# DCC1_SR2 register map
Vendor: Texas Instruments
Peripheral module from a debugger description file (folder DM50x).
Registers are 32-bit, access per field, reset 0x0 unless marked. A register's access mark holds for its fields unless they carry their own. Offsets are as the file gives them; lines under a group give offsets from that group; [hi:lo] are bit positions; {n}, {i} and the like mark numbered series; 'fields as' and 'values as' point back to an identical list; <NAME> marks a mode.

## DCC1_SR2
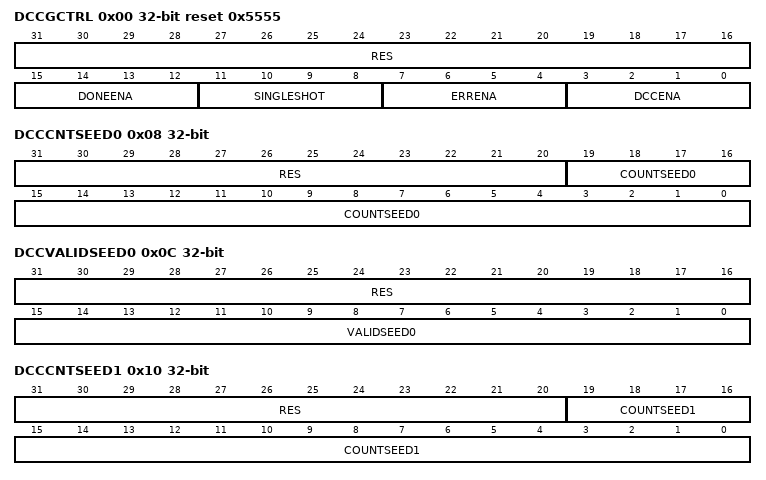
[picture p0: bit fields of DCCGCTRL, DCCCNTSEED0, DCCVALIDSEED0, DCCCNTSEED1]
0x00 DCCGCTRL reset 0x5555 — DCC Global Control RegisterNOTE: For SR1.0 physical addresses, see
  [31:16] RES ro — User, privilege, and debug mode reads return 0 and writes have no effect
  [15:12] DONEENA rw — The DONEENA bit enables/disables the done interrupt signal, but has no effect on the done status flag inDCCSTAT register. User, privilege, and debug mode (read): 0101 = the done signal is disabled others = the done signal is enabled Privilege and debug mode (write): 0101 = disable done signal generation others = enable done signal generation
  [11:8] SINGLESHOT rw — The SINGLESHOT bit enables/disables repetitive operation of the DCC. User, privilege, and debug mode (read): 1010 = stop counting when counter0 and valid0 both reach zero 1011 = stop counting when counter1 reaches zero others = continuously repeat (until error) Privilege and debug mode (write): 1010 = stop counting when counter0 and valid0 both reach zero 1011 = stop counting when counter1 reaches zero others = continuously repeat (until error)
  [7:4] ERRENA rw — The ERRENA bit enables/disables the error signal. User, privilege, and debug mode (read): 0101 = the error signal is disabled others = the error signal is enabled Privilege and debug mode (write): 0101 = disable error signal generation others = enable error signal generation
  [3:0] DCCENA rw — The DCCENA bit starts and stops the operation of the dcc. User, privilege, and debug mode (read): 0101 = counters are stopped others = counters are running Privilege and debug mode (write): 0101 = stop counters and error-checking others = load the counters with their seed values and begin counting
0x04 DCCREV ro reset not defined — DCC Revision IDNOTE: For SR1.0 physical addresses, see
  [31:0] REVISION — IP Revision
0x08 DCCCNTSEED0 — Count0 Seed Value RegisterNOTE: For SR1.0 physical addresses, see
  [31:20] RES ro — User, privilege, and debug mode reads return 0 and writes have no effect
  [19:0] COUNTSEED0 rw — This field contains the seed value that gets loaded into counter 0 (clock source 0). User, privilege, and debug mode (read): Returns the current seed value for COUNT0. Privilege and debug mode (write): Sets the current seed value for COUNT0.
0x0C DCCVALIDSEED0 — Valid0 Seed Value RegisterNOTE: For SR1.0 physical addresses, see
  [31:16] RES ro — User, privilege, and debug mode reads return 0 and writes have no effect
  [15:0] VALIDSEED0 rw — This field contains the seed value that gets loaded into the valid duration counter for clock source 0. User, privilege, and debug mode (read): Returns the current seed value for VALID0. Privilege and debug mode (write): Sets the current seed value for VALID0.
0x10 DCCCNTSEED1 — Count1 Seed Value RegisterNOTE: For SR1.0 physical addresses, see
  [31:20] RES ro — User, privilege, and debug mode reads return 0 and writes have no effect
  [19:0] COUNTSEED1 rw — This field contains the seed value that gets loaded into counter 1 (clock source 1). User, privilege, and debug mode (read): Returns the current seed value for COUNT1. Privilege and debug mode (write): Sets the current seed value for COUNT1.
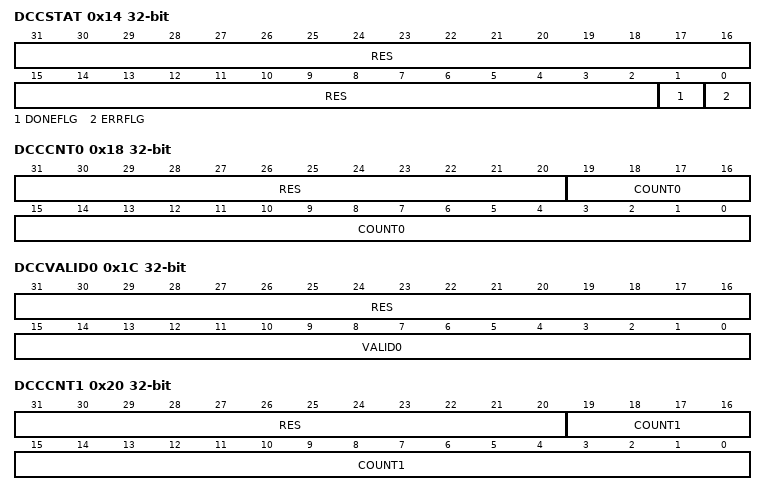
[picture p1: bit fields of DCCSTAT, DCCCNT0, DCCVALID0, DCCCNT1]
0x14 DCCSTAT — DCC Status RegisterNOTE: For SR1.0 physical addresses, see
  [31:2] RES ro
  [1] DONEFLG rw — Indicates when single-shot mode is complete without error. Writing a ?1? to this bit clears the flag. User, privilege, and debug mode (read): 0 = single-shot mode is not done 1 = single-shot mode is done Privilege and debug mode (write): 0 = no effect 1 = clear the done flag
  [0] ERRFLG rw — Indicates whether or not an error has occurred. Writing a ?1? to this bit clears the flag. User, privilege, and debug mode (read): 0 = an error has not occurred 1 = an error has occurred Privilege and debug mode (write): 0 = no effect 1 = clear the error flag
0x18 DCCCNT0 ro — Count0 Value RegisterNOTE: For SR1.0 physical addresses, see
  [31:20] RES — User, privilege, and debug mode reads return 0 and writes have no effect
  [19:0] COUNT0 — This field contains the current value of counter 0. User, privilege, and debug mode (read): Returns the current value for counter 0. Privilege and debug mode (write): Writes have no effect.
0x1C DCCVALID0 ro — Valid0 Value RegisterNOTE: For SR1.0 physical addresses, see
  [31:16] RES — User, privilege, and debug mode reads return 0 and writes have no effect
  [15:0] VALID0 — This field contains the current value of valid counter 0. User, privilege, and debug mode (read): Returns the current value for valid counter 0. Privilege and debug mode (write): writes have no effect.
0x20 DCCCNT1 ro — Count1 Value RegisterNOTE: For SR1.0 physical addresses, see
  [31:20] RES — User, privilege, and debug mode reads return 0 and writes have no effect
  [19:0] COUNT1 — This field contains the current value of counter 1. User, privilege, and debug mode (read): Returns the current value for counter 1. Privilege and debug mode (write): writes have no effect.
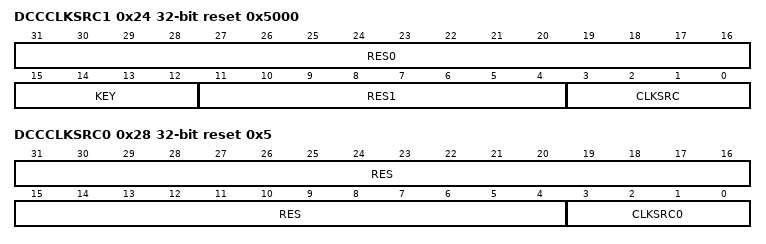
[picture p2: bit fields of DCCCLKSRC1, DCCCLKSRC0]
0x24 DCCCLKSRC1 reset 0x5000 — Clock Source Selection Register 1NOTE: For SR1.0 physical addresses, see
  [31:16] RES0 ro — User, privilege, and debug mode reads return 0 and writes have no effect
  [15:12] KEY rw — This field enables or disables clock source selection. User, privilege, and debug mode (read): Returns the current value of the key. Privilege and debug mode (write): Sets the key value. Key values: 1010: The CLKSRC field selects the clock source for COUNT1. others: Clock source selection is disabled. The secondary oscillator (clock source 1) is selected for COUNT1.
  [11:4] RES1 ro — User, privilege, and debug mode reads return 0 and writes have no effect
  [3:0] CLKSRC rw — This field specifies the clock source for COUNT1, when the KEY field enables this feature. User, privilege, and debug mode (read): Returns the current value of CLKSRC. Privilege and debug mode (write): Sets the value of CLKSRC. Clock Source values: 0000: Clock source 0 is selected for COUNT1. 0001: Clock source 1 is selected for COUNT1. 0010: Clock source 2 is selected for COUNT1. 0011: Clock source 3 is selected for COUNT1. 0100: Clock source 4 is selected for COUNT1. 0101: Clock source 5 is selected for COUNT1. 0110: Clock source 6 is selected for COUNT1. 0111: Clock source 7 is selected for COUNT1. 1000-1111: VCLK is selected for COUNT1.
0x28 DCCCLKSRC0 reset 0x5 — Clock Source Selection Register 0NOTE: For SR1.0 physical addresses, see
  [31:4] RES ro — User, privilege, and debug mode reads return 0 and writes have no effect
  [3:0] CLKSRC0 rw — This field specifies the clock source for COUNT0. User, privilege, and debug mode (read): Returns the current value of CLKSRC0. Privilege and debug mode (write): Sets the value of CLKSRC0. Clock Source values: 0101: Clock0[2] is selected as source for COUNT0. 1010: Clock0[1] is selected as source for COUNT0. other values: Clock0[0] is selected as source for COUNT0.
